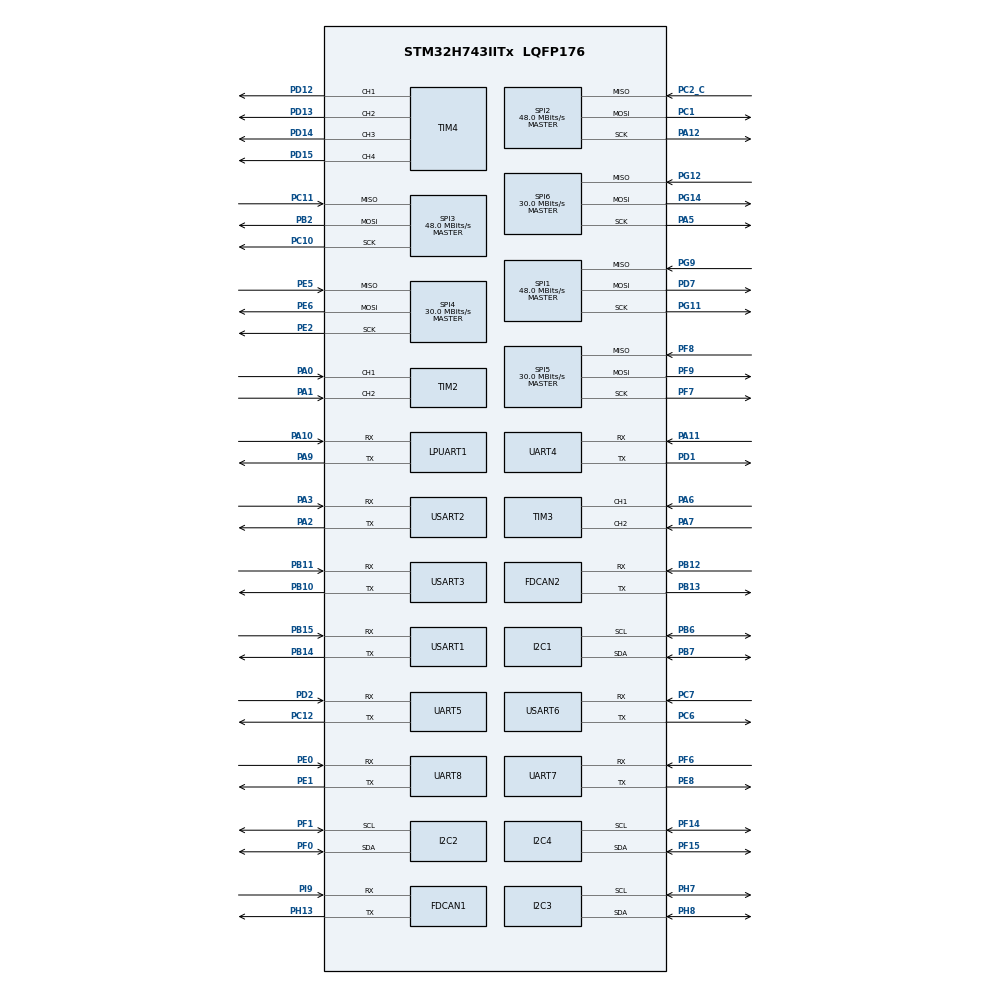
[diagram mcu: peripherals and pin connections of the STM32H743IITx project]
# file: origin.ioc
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CORTEX_M7.default_mode_Activation=1
Dma.Request0=USART1_RX
Dma.Request1=USART1_TX
Dma.Request2=USART6_RX
Dma.Request3=USART6_TX
Dma.USART1_RX.0.Direction=DMA_PERIPH_TO_MEMORY
Dma.USART1_RX.0.EventEnable=DISABLE
Dma.USART1_RX.0.FIFOMode=DMA_FIFOMODE_DISABLE
Dma.USART1_RX.0.Instance=DMA2_Stream2
Dma.USART1_RX.0.MemDataAlignment=DMA_MDATAALIGN_BYTE
Dma.USART1_RX.0.MemInc=DMA_MINC_ENABLE
Dma.USART1_RX.0.Mode=DMA_CIRCULAR
Dma.USART1_RX.0.PeriphDataAlignment=DMA_PDATAALIGN_BYTE
Dma.USART1_RX.0.PeriphInc=DMA_PINC_DISABLE
Dma.USART1_RX.0.Polarity=HAL_DMAMUX_REQ_GEN_RISING
Dma.USART1_RX.0.Priority=DMA_PRIORITY_HIGH
Dma.USART1_RX.0.RequestNumber=1
Dma.USART1_RX.0.SignalID=NONE
Dma.USART1_RX.0.SyncEnable=DISABLE
Dma.USART1_RX.0.SyncPolarity=HAL_DMAMUX_SYNC_NO_EVENT
Dma.USART1_RX.0.SyncRequestNumber=1
Dma.USART1_RX.0.SyncSignalID=NONE
Dma.USART1_TX.1.Direction=DMA_MEMORY_TO_PERIPH
Dma.USART1_TX.1.EventEnable=DISABLE
Dma.USART1_TX.1.FIFOMode=DMA_FIFOMODE_DISABLE
Dma.USART1_TX.1.Instance=DMA2_Stream7
Dma.USART1_TX.1.MemDataAlignment=DMA_MDATAALIGN_BYTE
Dma.USART1_TX.1.MemInc=DMA_MINC_ENABLE
Dma.USART1_TX.1.Mode=DMA_NORMAL
Dma.USART1_TX.1.PeriphDataAlignment=DMA_PDATAALIGN_BYTE
Dma.USART1_TX.1.PeriphInc=DMA_PINC_DISABLE
Dma.USART1_TX.1.Polarity=HAL_DMAMUX_REQ_GEN_RISING
Dma.USART1_TX.1.Priority=DMA_PRIORITY_HIGH
Dma.USART1_TX.1.RequestNumber=1
Dma.USART1_TX.1.SignalID=NONE
Dma.USART1_TX.1.SyncEnable=DISABLE
Dma.USART1_TX.1.SyncPolarity=HAL_DMAMUX_SYNC_NO_EVENT
Dma.USART1_TX.1.SyncRequestNumber=1
Dma.USART1_TX.1.SyncSignalID=NONE
Dma.USART6_RX.2.Direction=DMA_PERIPH_TO_MEMORY
Dma.USART6_RX.2.EventEnable=DISABLE
Dma.USART6_RX.2.FIFOMode=DMA_FIFOMODE_DISABLE
Dma.USART6_RX.2.Instance=DMA1_Stream0
Dma.USART6_RX.2.MemDataAlignment=DMA_MDATAALIGN_BYTE
Dma.USART6_RX.2.MemInc=DMA_MINC_ENABLE
Dma.USART6_RX.2.Mode=DMA_NORMAL
Dma.USART6_RX.2.PeriphDataAlignment=DMA_PDATAALIGN_BYTE
Dma.USART6_RX.2.PeriphInc=DMA_PINC_DISABLE
Dma.USART6_RX.2.Polarity=HAL_DMAMUX_REQ_GEN_RISING
Dma.USART6_RX.2.Priority=DMA_PRIORITY_LOW
Dma.USART6_RX.2.RequestNumber=1
Dma.USART6_RX.2.SignalID=NONE
Dma.USART6_RX.2.SyncEnable=DISABLE
Dma.USART6_RX.2.SyncPolarity=HAL_DMAMUX_SYNC_NO_EVENT
Dma.USART6_RX.2.SyncRequestNumber=1
Dma.USART6_RX.2.SyncSignalID=NONE
Dma.USART6_TX.3.Direction=DMA_MEMORY_TO_PERIPH
Dma.USART6_TX.3.EventEnable=DISABLE
Dma.USART6_TX.3.FIFOMode=DMA_FIFOMODE_DISABLE
Dma.USART6_TX.3.Instance=DMA1_Stream1
Dma.USART6_TX.3.MemDataAlignment=DMA_MDATAALIGN_BYTE
Dma.USART6_TX.3.MemInc=DMA_MINC_ENABLE
Dma.USART6_TX.3.Mode=DMA_NORMAL
Dma.USART6_TX.3.PeriphDataAlignment=DMA_PDATAALIGN_BYTE
Dma.USART6_TX.3.PeriphInc=DMA_PINC_DISABLE
Dma.USART6_TX.3.Polarity=HAL_DMAMUX_REQ_GEN_RISING
Dma.USART6_TX.3.Priority=DMA_PRIORITY_LOW
Dma.USART6_TX.3.RequestNumber=1
Dma.USART6_TX.3.SignalID=NONE
Dma.USART6_TX.3.SyncEnable=DISABLE
Dma.USART6_TX.3.SyncPolarity=HAL_DMAMUX_SYNC_NO_EVENT
Dma.USART6_TX.3.SyncRequestNumber=1
Dma.USART6_TX.3.SyncSignalID=NONE
FDCAN1.CalculateBaudRateNominal=500000
FDCAN1.CalculateTimeBitNominal=2000
FDCAN1.CalculateTimeQuantumNominal=666.6666666666666
FDCAN2.CalculateBaudRateNominal=500000
FDCAN2.CalculateTimeBitNominal=2000
FDCAN2.CalculateTimeQuantumNominal=666.6666666666666
I2C1.Timing=0x307075B1
I2C2.Timing=0x307075B1
I2C3.Timing=0x307075B1
I2C4.Timing=0x307075B1
Mcu.Family=STM32H7
Mcu.Name=STM32H743IITx
Mcu.Package=LQFP176
NVIC.DMA1_Stream0_IRQn=true\:0\:0\:false\:false\:true\:false\:true\:true
NVIC.DMA1_Stream1_IRQn=true\:0\:0\:false\:false\:true\:false\:true\:true
NVIC.DMA2_Stream2_IRQn=true\:0\:0\:false\:false\:true\:false\:true\:true
NVIC.DMA2_Stream7_IRQn=true\:0\:0\:false\:false\:true\:false\:true\:true
NVIC.PriorityGroup=NVIC_PRIORITYGROUP_4
NVIC.USART1_IRQn=true\:0\:0\:false\:false\:true\:true\:true\:true
NVIC.USART6_IRQn=true\:0\:0\:false\:false\:true\:true\:true\:true
PA0.Signal=S_TIM2_CH1_ETR
PA1.Signal=S_TIM2_CH2
PA10.Mode=Asynchronous
PA10.Signal=LPUART1_RX
PA11.Mode=Asynchronous
PA11.Signal=UART4_RX
PA12.Mode=Full_Duplex_Master
PA12.Signal=SPI2_SCK
PA13\ (JTMS/SWDIO).Mode=Serial_Wire
PA13\ (JTMS/SWDIO).Signal=DEBUG_JTMS-SWDIO
PA14\ (JTCK/SWCLK).Mode=Serial_Wire
PA14\ (JTCK/SWCLK).Signal=DEBUG_JTCK-SWCLK
PA2.Mode=Asynchronous
PA2.Signal=USART2_TX
PA3.Mode=Asynchronous
PA3.Signal=USART2_RX
PA5.Mode=Full_Duplex_Master
PA5.Signal=SPI6_SCK
PA6.Signal=S_TIM3_CH1
PA7.Signal=S_TIM3_CH2
PA9.Mode=Asynchronous
PA9.Signal=LPUART1_TX
PB10.Mode=Asynchronous
PB10.Signal=USART3_TX
PB11.Mode=Asynchronous
PB11.Signal=USART3_RX
PB12.Mode=FDCAN_Activate
PB12.Signal=FDCAN2_RX
PB13.Mode=FDCAN_Activate
PB13.Signal=FDCAN2_TX
PB14.GPIO_Speed=GPIO_SPEED_FREQ_LOW
PB14.Mode=Asynchronous
PB14.Signal=USART1_TX
PB15.GPIO_Speed=GPIO_SPEED_FREQ_LOW
PB15.Mode=Asynchronous
PB15.Signal=USART1_RX
PB2.Mode=Full_Duplex_Master
PB2.Signal=SPI3_MOSI
PB6.Mode=I2C
PB6.Signal=I2C1_SCL
PB7.Mode=I2C
PB7.Signal=I2C1_SDA
PC1.Mode=Full_Duplex_Master
PC1.Signal=SPI2_MOSI
PC10.Mode=Full_Duplex_Master
PC10.Signal=SPI3_SCK
PC11.Mode=Full_Duplex_Master
PC11.Signal=SPI3_MISO
PC12.Mode=Asynchronous
PC12.Signal=UART5_TX
PC2_C.Mode=Full_Duplex_Master
PC2_C.Signal=SPI2_MISO
PC6.Mode=Asynchronous
PC6.Signal=USART6_TX
PC7.Mode=Asynchronous
PC7.Signal=USART6_RX
PD1.Mode=Asynchronous
PD1.Signal=UART4_TX
PD12.Signal=S_TIM4_CH1
PD13.Signal=S_TIM4_CH2
PD14.Signal=S_TIM4_CH3
PD15.Signal=S_TIM4_CH4
PD2.Mode=Asynchronous
PD2.Signal=UART5_RX
PD7.Mode=Full_Duplex_Master
PD7.Signal=SPI1_MOSI
PE0.Mode=Asynchronous
PE0.Signal=UART8_RX
PE1.Mode=Asynchronous
PE1.Signal=UART8_TX
PE2.Mode=Full_Duplex_Master
PE2.Signal=SPI4_SCK
PE5.Mode=Full_Duplex_Master
PE5.Signal=SPI4_MISO
PE6.Mode=Full_Duplex_Master
PE6.Signal=SPI4_MOSI
PE8.Mode=Asynchronous
PE8.Signal=UART7_TX
PF0.Mode=I2C
PF0.Signal=I2C2_SDA
PF1.Mode=I2C
PF1.Signal=I2C2_SCL
PF14.Mode=I2C
PF14.Signal=I2C4_SCL
PF15.Mode=I2C
PF15.Signal=I2C4_SDA
PF6.Mode=Asynchronous
PF6.Signal=UART7_RX
PF7.Mode=Full_Duplex_Master
PF7.Signal=SPI5_SCK
PF8.Mode=Full_Duplex_Master
PF8.Signal=SPI5_MISO
PF9.Mode=Full_Duplex_Master
PF9.Signal=SPI5_MOSI
PG11.Mode=Full_Duplex_Master
PG11.Signal=SPI1_SCK
PG12.Mode=Full_Duplex_Master
PG12.Signal=SPI6_MISO
PG14.Mode=Full_Duplex_Master
PG14.Signal=SPI6_MOSI
PG9.Mode=Full_Duplex_Master
PG9.Signal=SPI1_MISO
PH0-OSC_IN\ (PH0).Mode=HSE-External-Oscillator
PH0-OSC_IN\ (PH0).Signal=RCC_OSC_IN
PH1-OSC_OUT\ (PH1).Mode=HSE-External-Oscillator
PH1-OSC_OUT\ (PH1).Signal=RCC_OSC_OUT
PH13.Mode=FDCAN_Activate
PH13.Signal=FDCAN1_TX
PH7.Mode=I2C
PH7.Signal=I2C3_SCL
PH8.Mode=I2C
PH8.Signal=I2C3_SDA
PI9.Mode=FDCAN_Activate
PI9.Signal=FDCAN1_RX
ProjectManager.HeapSize=0x200
ProjectManager.StackSize=0x400
ProjectManager.TargetToolchain=MDK-ARM V5.32
RCC.ADCFreq_Value=48375000
RCC.APB1Freq_Value=120000000
RCC.APB2Freq_Value=120000000
RCC.APB3Freq_Value=120000000
RCC.APB4Freq_Value=120000000
RCC.CortexFreq_Value=480000000
RCC.D1PPRE=RCC_APB3_DIV2
RCC.D2PPRE1=RCC_APB1_DIV2
RCC.D2PPRE2=RCC_APB2_DIV2
RCC.D3PPRE=RCC_APB4_DIV2
RCC.DIVM1=2
RCC.DIVN1=80
RCC.DIVQ1=5
RCC.FDCANCLockSelection=RCC_FDCANCLKSOURCE_HSE
RCC.HCLKFreq_Value=240000000
RCC.HPRE=RCC_HCLK_DIV2
RCC.HSE_VALUE=24000000
RCC.PLL2FRACN=0
RCC.PLL3FRACN=0
RCC.PLLFRACN=0
RCC.PLLSourceVirtual=RCC_PLLSOURCE_HSE
RCC.SYSCLKFreq_VALUE=480000000
RCC.SYSCLKSource=RCC_SYSCLKSOURCE_PLLCLK
RCC.USBFreq_Value=192000000
SH.S_TIM2_CH1_ETR.0=TIM2_CH1,Encoder_Interface
SH.S_TIM2_CH2.0=TIM2_CH2,Encoder_Interface
SH.S_TIM3_CH1.0=TIM3_CH1,Encoder_Interface
SH.S_TIM3_CH2.0=TIM3_CH2,Encoder_Interface
SH.S_TIM4_CH1.0=TIM4_CH1,PWM Generation1 CH1
SH.S_TIM4_CH2.0=TIM4_CH2,PWM Generation2 CH2
SH.S_TIM4_CH3.0=TIM4_CH3,PWM Generation3 CH3
SH.S_TIM4_CH4.0=TIM4_CH4,PWM Generation4 CH4
SPI1.BaudRatePrescaler=SPI_BAUDRATEPRESCALER_4
SPI1.CalculateBaudRate=48.0 MBits/s
SPI1.Direction=SPI_DIRECTION_2LINES
SPI1.Mode=SPI_MODE_MASTER
SPI1.VirtualType=VM_MASTER
SPI2.BaudRatePrescaler=SPI_BAUDRATEPRESCALER_4
SPI2.CalculateBaudRate=48.0 MBits/s
SPI2.Direction=SPI_DIRECTION_2LINES
SPI2.Mode=SPI_MODE_MASTER
SPI2.VirtualType=VM_MASTER
SPI3.BaudRatePrescaler=SPI_BAUDRATEPRESCALER_4
SPI3.CalculateBaudRate=48.0 MBits/s
SPI3.Direction=SPI_DIRECTION_2LINES
SPI3.Mode=SPI_MODE_MASTER
SPI3.VirtualType=VM_MASTER
SPI4.BaudRatePrescaler=SPI_BAUDRATEPRESCALER_4
SPI4.CalculateBaudRate=30.0 MBits/s
SPI4.Direction=SPI_DIRECTION_2LINES
SPI4.Mode=SPI_MODE_MASTER
SPI4.VirtualType=VM_MASTER
SPI5.BaudRatePrescaler=SPI_BAUDRATEPRESCALER_4
SPI5.CalculateBaudRate=30.0 MBits/s
SPI5.Direction=SPI_DIRECTION_2LINES
SPI5.Mode=SPI_MODE_MASTER
SPI5.VirtualType=VM_MASTER
SPI6.BaudRatePrescaler=SPI_BAUDRATEPRESCALER_4
SPI6.CalculateBaudRate=30.0 MBits/s
SPI6.Direction=SPI_DIRECTION_2LINES
SPI6.Mode=SPI_MODE_MASTER
SPI6.VirtualType=VM_MASTER
TIM4.Channel-PWM\ Generation1\ CH1=TIM_CHANNEL_1
TIM4.Channel-PWM\ Generation2\ CH2=TIM_CHANNEL_2
TIM4.Channel-PWM\ Generation3\ CH3=TIM_CHANNEL_3
TIM4.Channel-PWM\ Generation4\ CH4=TIM_CHANNEL_4
USART1.VirtualMode-Asynchronous=VM_ASYNC
USART2.VirtualMode-Asynchronous=VM_ASYNC
USART3.VirtualMode-Asynchronous=VM_ASYNC
USART6.VirtualMode-Asynchronous=VM_ASYNC
VP_MEMORYMAP_VS_MEMORYMAP.Mode=CurAppReg
VP_TIM4_VS_ClockSourceINT.Mode=Internal
board=custom

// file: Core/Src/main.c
/* USER CODE BEGIN Header */
/**
  ******************************************************************************
  * @file           : main.c
  * @brief          : Main program body
  ******************************************************************************
  * @attention
  *
  * Copyright (c) 2025 STMicroelectronics.
  * All rights reserved.
  *
  * This software is licensed under terms that can be found in the LICENSE file
  * in the root directory of this software component.
  * If no LICENSE file comes with this software, it is provided AS-IS.
  *
  ******************************************************************************
  */
/* USER CODE END Header */
#include "main.h"
#include "dma.h"
#include "fdcan.h"
#include "i2c.h"
#include "usart.h"
#include "memorymap.h"
#include "spi.h"
#include "tim.h"
#include "gpio.h"

void SystemClock_Config(void);
static void MPU_Config(void);

int main(void)
{

  /* MPU Configuration--------------------------------------------------------*/
  MPU_Config();

  /* MCU Configuration--------------------------------------------------------*/

  /* Reset of all peripherals, Initializes the Flash interface and the Systick. */
  HAL_Init();

  /* Configure the system clock */
  SystemClock_Config();

  /* Initialize all configured peripherals */
  MX_GPIO_Init();
  MX_DMA_Init();
  MX_FDCAN1_Init();
  MX_FDCAN2_Init();
  MX_I2C1_Init();
  MX_I2C2_Init();
  MX_I2C3_Init();
  MX_I2C4_Init();
  MX_SPI1_Init();
  MX_SPI2_Init();
  MX_SPI3_Init();
  MX_SPI4_Init();
  MX_SPI5_Init();
  MX_SPI6_Init();
  MX_UART4_Init();
  MX_UART5_Init();
  MX_UART7_Init();
  MX_UART8_Init();
  MX_USART1_UART_Init();
  MX_USART2_UART_Init();
  MX_USART3_UART_Init();
  MX_USART6_UART_Init();
  MX_LPUART1_UART_Init();
  MX_TIM2_Init();
  MX_TIM3_Init();
  MX_TIM4_Init();
  /* USER CODE BEGIN 2 */
	//串口1接收函数
 	__HAL_UART_CLEAR_IDLEFLAG(&huart1); 											// 清除IDLE标志
	__HAL_UART_ENABLE_IT(&huart1, UART_IT_IDLE); 							// 使能串UART1 IDLE中断
  HAL_UART_Receive_DMA(&huart1, (uint8_t *)rxCmd, CMD_LEN); // 开启DMA接收模式
	//串口6加dma，不定长度

	HAL_UART_Transmit(&huart1,(uint8_t*)12,4,HAL_MAX_DELAY);
// 	/**********************************************************
// ***	上电延时2秒等待Emm_V5.0闭环初始化完毕
// **********************************************************/
// 	// HAL_Delay(2000);

// /**********************************************************
// ***	地址1电机：位置模式，方向CW，速度1000RPM，加速度0（不使用加减速直接启动），脉冲数3200（16细分下发送3200个脉冲电机转一圈），相对运动
// **********************************************************/
// Step_Pos_Control(1, 0, 1000, 0, 3200, 0, 0); // 多机同步标志位置1
// 	HAL_Delay(10);																 // 每条命令后面延时10毫秒，防止粘包

// /**********************************************************
// ***	地址2电机：位置模式，方向CW，速度1000RPM，加速度0（不使用加减速直接启动），脉冲数3200（16细分下发送3200个脉冲电机转一圈），相对运动
// **********************************************************/
// Step_Pos_Control(2, 0, 1000, 0, 3200, 0, 0); // 多机同步标志位置1
// 	HAL_Delay(10);																 // 每条命令后面延时10毫秒，防止粘包
// 	/**********************************************************
// 	***	触发多机同步开始运动
// **********************************************************/
//   Step_Synchronous_motion(0); 								 // 广播地址0触发
// 	HAL_Delay(10);																 // 每条命令后面延时10毫秒，防止粘包
// 	/**********************************************************
// ***	等待返回到位命令，命令数据缓存在数组rxCmd上，长度为rxCount
// **********************************************************/
// //	while(rxCmd[1] != 0xFD || rxCmd[2] != 0x9F); rxFrameFlag = false;
  /* USER CODE END 2 */

  /* Infinite loop */
  while (1)
  {

  }
}

void SystemClock_Config(void)
{
  RCC_OscInitTypeDef RCC_OscInitStruct = {0};
  RCC_ClkInitTypeDef RCC_ClkInitStruct = {0};

  /** Supply configuration update enable
  */
  HAL_PWREx_ConfigSupply(PWR_LDO_SUPPLY);

  /** Configure the main internal regulator output voltage
  */
  __HAL_PWR_VOLTAGESCALING_CONFIG(PWR_REGULATOR_VOLTAGE_SCALE0);

  while(!__HAL_PWR_GET_FLAG(PWR_FLAG_VOSRDY)) {}

  /** Initializes the RCC Oscillators according to the specified parameters
  * in the RCC_OscInitTypeDef structure.
  */
  RCC_OscInitStruct.OscillatorType = RCC_OSCILLATORTYPE_HSE;
  RCC_OscInitStruct.HSEState = RCC_HSE_ON;
  RCC_OscInitStruct.PLL.PLLState = RCC_PLL_ON;
  RCC_OscInitStruct.PLL.PLLSource = RCC_PLLSOURCE_HSE;
  RCC_OscInitStruct.PLL.PLLM = 2;
  RCC_OscInitStruct.PLL.PLLN = 80;
  RCC_OscInitStruct.PLL.PLLP = 2;
  RCC_OscInitStruct.PLL.PLLQ = 5;
  RCC_OscInitStruct.PLL.PLLR = 2;
  RCC_OscInitStruct.PLL.PLLRGE = RCC_PLL1VCIRANGE_3;
  RCC_OscInitStruct.PLL.PLLVCOSEL = RCC_PLL1VCOWIDE;
  RCC_OscInitStruct.PLL.PLLFRACN = 0;
  if (HAL_RCC_OscConfig(&RCC_OscInitStruct) != HAL_OK)
  {
    Error_Handler();
  }

  /** Initializes the CPU, AHB and APB buses clocks
  */
  RCC_ClkInitStruct.ClockType = RCC_CLOCKTYPE_HCLK|RCC_CLOCKTYPE_SYSCLK
                              |RCC_CLOCKTYPE_PCLK1|RCC_CLOCKTYPE_PCLK2
                              |RCC_CLOCKTYPE_D3PCLK1|RCC_CLOCKTYPE_D1PCLK1;
  RCC_ClkInitStruct.SYSCLKSource = RCC_SYSCLKSOURCE_PLLCLK;
  RCC_ClkInitStruct.SYSCLKDivider = RCC_SYSCLK_DIV1;
  RCC_ClkInitStruct.AHBCLKDivider = RCC_HCLK_DIV2;
  RCC_ClkInitStruct.APB3CLKDivider = RCC_APB3_DIV2;
  RCC_ClkInitStruct.APB1CLKDivider = RCC_APB1_DIV2;
  RCC_ClkInitStruct.APB2CLKDivider = RCC_APB2_DIV2;
  RCC_ClkInitStruct.APB4CLKDivider = RCC_APB4_DIV2;

  if (HAL_RCC_ClockConfig(&RCC_ClkInitStruct, FLASH_LATENCY_4) != HAL_OK)
  {
    Error_Handler();
  }
}

 /* MPU Configuration */

void MPU_Config(void)
{
  MPU_Region_InitTypeDef MPU_InitStruct = {0};

  /* Disables the MPU */
  HAL_MPU_Disable();

  /** Initializes and configures the Region and the memory to be protected
  */
  MPU_InitStruct.Enable = MPU_REGION_ENABLE;
  MPU_InitStruct.Number = MPU_REGION_NUMBER0;
  MPU_InitStruct.BaseAddress = 0x0;
  MPU_InitStruct.Size = MPU_REGION_SIZE_4GB;
  MPU_InitStruct.SubRegionDisable = 0x87;
  MPU_InitStruct.TypeExtField = MPU_TEX_LEVEL0;
  MPU_InitStruct.AccessPermission = MPU_REGION_NO_ACCESS;
  MPU_InitStruct.DisableExec = MPU_INSTRUCTION_ACCESS_DISABLE;
  MPU_InitStruct.IsShareable = MPU_ACCESS_SHAREABLE;
  MPU_InitStruct.IsCacheable = MPU_ACCESS_NOT_CACHEABLE;
  MPU_InitStruct.IsBufferable = MPU_ACCESS_NOT_BUFFERABLE;

  HAL_MPU_ConfigRegion(&MPU_InitStruct);
  /* Enables the MPU */
  HAL_MPU_Enable(MPU_PRIVILEGED_DEFAULT);

}

void Error_Handler(void)
{
  __disable_irq();
  while (1)
  {
  }
}
